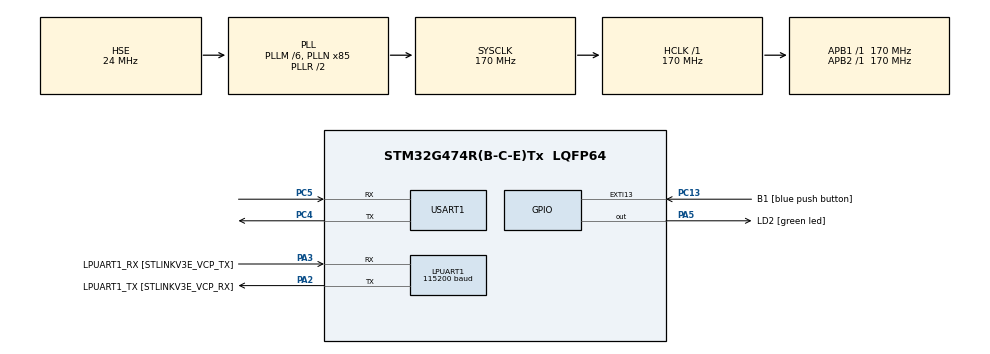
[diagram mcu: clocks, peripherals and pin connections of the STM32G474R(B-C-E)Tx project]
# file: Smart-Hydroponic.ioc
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Mcu.Family=STM32G4
RCC.CortexFreq_Value=170000000
PA14.GPIO_Label=T_SWCLK
LPUART1.WordLength=UART_WORDLENGTH_8B
PC5.Mode=Asynchronous
PC13.GPIO_Label=B1 [blue push button]
RCC.SYSCLKSource=RCC_SYSCLKSOURCE_PLLCLK
ProjectManager.StackSize=0x400
FREERTOS.configENABLE_FPU=1
RCC.HCLKFreq_Value=170000000
RCC.APB2TimFreq_Value=170000000
RCC.AHBFreq_Value=170000000
NVIC.EXTI15_10_IRQn=true\:5\:0\:false\:false\:true\:true\:true\:true
RCC.HSE_VALUE=24000000
FREERTOS.configUSE_TIMERS=1
RCC.RTCClockSelection=RCC_RTCCLKSOURCE_LSE
RCC.ADC12Freq_Value=170000000
PC14-OSC32_IN.Mode=LSE-External-Oscillator
PA14.Mode=Serial_Wire
VP_SYS_VS_tim1.Mode=TIM1
VP_SYS_VS_DBSignals.Mode=DisableDeadBatterySignals
VP_FREERTOS_VS_CMSIS_V1.Mode=CMSIS_V1
Mcu.Package=LQFP64
NVIC.TimeBase=TIM1_UP_TIM16_IRQn
PA2.GPIO_Label=LPUART1_TX [STLINKV3E_VCP_RX]
NVIC.TimeBaseIP=TIM1
RCC.APB1TimFreq_Value=170000000
PC5.Signal=USART1_RX
NVIC.USART1_IRQn=true\:6\:0\:true\:false\:true\:true\:true\:true
PF1-OSC_OUT.Mode=HSE-External-Oscillator
PF1-OSC_OUT.Signal=RCC_OSC_OUT
PC4.Mode=Asynchronous
RCC.HSI48_VALUE=48000000
PA3.Signal=LPUART1_RX
PB3.GPIO_Label=T_SWO
RCC.PLLSourceVirtual=RCC_PLLSOURCE_HSE
PC15-OSC32_OUT.Mode=LSE-External-Oscillator
FREERTOS.Tasks01=defaultTask,0,128,StartDefaultTask,Default,NULL,Dynamic,NULL,NULL
PC13.Signal=GPXTI13
PC4.Signal=USART1_TX
RCC.EXTERNAL_CLOCK_VALUE=12288000
VP_RNG_VS_RNG.Mode=RNG_Activate
PC14-OSC32_IN.Signal=RCC_OSC32_IN
USART1.VirtualMode-Asynchronous=VM_ASYNC
PA13.Signal=SYS_JTMS-SWDIO
PA3.Mode=Asynchronous
ProjectManager.TargetToolchain=STM32CubeIDE
RCC.USBFreq_Value=42500000
PC15-OSC32_OUT.Signal=RCC_OSC32_OUT
PF0-OSC_IN.Mode=HSE-External-Oscillator
PA5.Signal=GPIO_Output
FREERTOS.MEMORY_ALLOCATION=2
board=NUCLEO-G474RE
RCC.VCOOutputFreq_Value=340000000
RCC.ADC345Freq_Value=170000000
RCC.APB2Freq_Value=170000000
PA13.Mode=Serial_Wire
Mcu.Name=STM32G474R(B-C-E)Tx
LPUART1.BaudRate=115200
PA13.GPIO_Label=T_SWDIO
PA2.Signal=LPUART1_TX
PB3.Signal=SYS_JTDO-SWO
RCC.SYSCLKFreq_VALUE=170000000
PA5.GPIO_Label=LD2 [green led]
PA14.Signal=SYS_JTCK-SWCLK
ProjectManager.HeapSize=0x200
RCC.HSI_VALUE=16000000
NVIC.TIM1_UP_TIM16_IRQn=true\:0\:0\:false\:false\:true\:false\:false\:true
RCC.PLLQ=RCC_PLLQ_DIV8
NVIC.PriorityGroup=NVIC_PRIORITYGROUP_4
RCC.PLLM=RCC_PLLM_DIV6
RCC.PLLN=85
PA2.Mode=Asynchronous
PF0-OSC_IN.Signal=RCC_OSC_IN
RCC.APB1Freq_Value=170000000
PA3.GPIO_Label=LPUART1_RX [STLINKV3E_VCP_TX]

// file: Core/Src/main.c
/* USER CODE BEGIN Header */
/**
  ******************************************************************************
  * @file           : main.c
  * @brief          : Main program body
  ******************************************************************************
  * @attention
  *
  * <h2><center>&copy; Copyright (c) 2022 STMicroelectronics.
  * All rights reserved.</center></h2>
  *
  * This software component is licensed by ST under BSD 3-Clause license,
  * the "License"; You may not use this file except in compliance with the
  * License. You may obtain a copy of the License at:
  *                        opensource.org/licenses/BSD-3-Clause
  *
  ******************************************************************************
  */
/* USER CODE END Header */
#include "main.h"
#include "cmsis_os.h"

/* USER CODE BEGIN Includes */
#include <stdio.h>
#include "app.h"

/* USER CODE END Includes */

UART_HandleTypeDef hlpuart1;
UART_HandleTypeDef huart1;

RNG_HandleTypeDef hrng;

osThreadId defaultTaskHandle;

void SystemClock_Config(void);
static void MX_GPIO_Init(void);
static void MX_LPUART1_UART_Init(void);
static void MX_USART1_UART_Init(void);
static void MX_RNG_Init(void);
void StartDefaultTask(void const * argument);

int main(void)
{

  /* MCU Configuration--------------------------------------------------------*/

  /* Reset of all peripherals, Initializes the Flash interface and the Systick. */
  HAL_Init();

  /* Configure the system clock */
  SystemClock_Config();

  /* Initialize all configured peripherals */
  MX_GPIO_Init();
  MX_LPUART1_UART_Init();
  MX_USART1_UART_Init();
  MX_RNG_Init();

  /* Create the thread(s) */
  /* definition and creation of defaultTask */
//  osThreadDef(defaultTask, StartDefaultTask, osPriorityNormal, 0, 128);
//  defaultTaskHandle = osThreadCreate(osThread(defaultTask), NULL);
//
//  /* USER CODE BEGIN RTOS_THREADS */
//////  /* add threads, ... */
//  /* USER CODE END RTOS_THREADS */
//
//  /* Start scheduler */
//  osKernelStart();

  /* We should never get here as control is now taken by the scheduler */
  /* Infinite loop */
  /* USER CODE BEGIN WHILE */

  while(!HAL_GPIO_ReadPin(B1_GPIO_Port, B1_Pin));		// Start button

  if(app_init()){

	  vTaskStartScheduler();
  }

  while (1)
  {

    /* USER CODE END WHILE */

  }
}
void SystemClock_Config(void)
{
  RCC_OscInitTypeDef RCC_OscInitStruct = {0};
  RCC_ClkInitTypeDef RCC_ClkInitStruct = {0};
  RCC_PeriphCLKInitTypeDef PeriphClkInit = {0};

  /** Configure the main internal regulator output voltage
  */
  HAL_PWREx_ControlVoltageScaling(PWR_REGULATOR_VOLTAGE_SCALE1_BOOST);
  /** Initializes the RCC Oscillators according to the specified parameters
  * in the RCC_OscInitTypeDef structure.
  */
  RCC_OscInitStruct.OscillatorType = RCC_OSCILLATORTYPE_HSE;
  RCC_OscInitStruct.HSEState = RCC_HSE_ON;
  RCC_OscInitStruct.PLL.PLLState = RCC_PLL_ON;
  RCC_OscInitStruct.PLL.PLLSource = RCC_PLLSOURCE_HSE;
  RCC_OscInitStruct.PLL.PLLM = RCC_PLLM_DIV6;
  RCC_OscInitStruct.PLL.PLLN = 85;
  RCC_OscInitStruct.PLL.PLLP = RCC_PLLP_DIV2;
  RCC_OscInitStruct.PLL.PLLQ = RCC_PLLQ_DIV8;
  RCC_OscInitStruct.PLL.PLLR = RCC_PLLR_DIV2;
  if (HAL_RCC_OscConfig(&RCC_OscInitStruct) != HAL_OK)
  {
    Error_Handler();
  }
  /** Initializes the CPU, AHB and APB buses clocks
  */
  RCC_ClkInitStruct.ClockType = RCC_CLOCKTYPE_HCLK|RCC_CLOCKTYPE_SYSCLK
                              |RCC_CLOCKTYPE_PCLK1|RCC_CLOCKTYPE_PCLK2;
  RCC_ClkInitStruct.SYSCLKSource = RCC_SYSCLKSOURCE_PLLCLK;
  RCC_ClkInitStruct.AHBCLKDivider = RCC_SYSCLK_DIV1;
  RCC_ClkInitStruct.APB1CLKDivider = RCC_HCLK_DIV1;
  RCC_ClkInitStruct.APB2CLKDivider = RCC_HCLK_DIV1;

  if (HAL_RCC_ClockConfig(&RCC_ClkInitStruct, FLASH_LATENCY_4) != HAL_OK)
  {
    Error_Handler();
  }
  /** Initializes the peripherals clocks
  */
  PeriphClkInit.PeriphClockSelection = RCC_PERIPHCLK_USART1|RCC_PERIPHCLK_LPUART1
                              |RCC_PERIPHCLK_RNG;
  PeriphClkInit.Usart1ClockSelection = RCC_USART1CLKSOURCE_PCLK2;
  PeriphClkInit.Lpuart1ClockSelection = RCC_LPUART1CLKSOURCE_PCLK1;
  PeriphClkInit.RngClockSelection = RCC_RNGCLKSOURCE_PLL;
  if (HAL_RCCEx_PeriphCLKConfig(&PeriphClkInit) != HAL_OK)
  {
    Error_Handler();
  }
}

static void MX_LPUART1_UART_Init(void)
{

  hlpuart1.Instance = LPUART1;
  hlpuart1.Init.BaudRate = 115200;
  hlpuart1.Init.WordLength = UART_WORDLENGTH_8B;
  hlpuart1.Init.StopBits = UART_STOPBITS_1;
  hlpuart1.Init.Parity = UART_PARITY_NONE;
  hlpuart1.Init.Mode = UART_MODE_TX_RX;
  hlpuart1.Init.HwFlowCtl = UART_HWCONTROL_NONE;
  hlpuart1.Init.OneBitSampling = UART_ONE_BIT_SAMPLE_DISABLE;
  hlpuart1.Init.ClockPrescaler = UART_PRESCALER_DIV1;
  hlpuart1.AdvancedInit.AdvFeatureInit = UART_ADVFEATURE_NO_INIT;
  if (HAL_UART_Init(&hlpuart1) != HAL_OK)
  {
    Error_Handler();
  }
  if (HAL_UARTEx_SetTxFifoThreshold(&hlpuart1, UART_TXFIFO_THRESHOLD_1_8) != HAL_OK)
  {
    Error_Handler();
  }
  if (HAL_UARTEx_SetRxFifoThreshold(&hlpuart1, UART_RXFIFO_THRESHOLD_1_8) != HAL_OK)
  {
    Error_Handler();
  }
  if (HAL_UARTEx_DisableFifoMode(&hlpuart1) != HAL_OK)
  {
    Error_Handler();
  }

}

static void MX_USART1_UART_Init(void)
{

  huart1.Instance = USART1;
  huart1.Init.BaudRate = 115200;
  huart1.Init.WordLength = UART_WORDLENGTH_8B;
  huart1.Init.StopBits = UART_STOPBITS_1;
  huart1.Init.Parity = UART_PARITY_NONE;
  huart1.Init.Mode = UART_MODE_TX_RX;
  huart1.Init.HwFlowCtl = UART_HWCONTROL_NONE;
  huart1.Init.OverSampling = UART_OVERSAMPLING_16;
  huart1.Init.OneBitSampling = UART_ONE_BIT_SAMPLE_DISABLE;
  huart1.Init.ClockPrescaler = UART_PRESCALER_DIV1;
  huart1.AdvancedInit.AdvFeatureInit = UART_ADVFEATURE_NO_INIT;
  if (HAL_UART_Init(&huart1) != HAL_OK)
  {
    Error_Handler();
  }
  if (HAL_UARTEx_SetTxFifoThreshold(&huart1, UART_TXFIFO_THRESHOLD_1_8) != HAL_OK)
  {
    Error_Handler();
  }
  if (HAL_UARTEx_SetRxFifoThreshold(&huart1, UART_RXFIFO_THRESHOLD_1_8) != HAL_OK)
  {
    Error_Handler();
  }
  if (HAL_UARTEx_DisableFifoMode(&huart1) != HAL_OK)
  {
    Error_Handler();
  }

}

static void MX_RNG_Init(void)
{

  hrng.Instance = RNG;
  hrng.Init.ClockErrorDetection = RNG_CED_ENABLE;
  if (HAL_RNG_Init(&hrng) != HAL_OK)
  {
    Error_Handler();
  }

}

static void MX_GPIO_Init(void)
{
  GPIO_InitTypeDef GPIO_InitStruct = {0};

  /* GPIO Ports Clock Enable */
  __HAL_RCC_GPIOC_CLK_ENABLE();
  __HAL_RCC_GPIOF_CLK_ENABLE();
  __HAL_RCC_GPIOA_CLK_ENABLE();
  __HAL_RCC_GPIOB_CLK_ENABLE();

  /*Configure GPIO pin Output Level */
  HAL_GPIO_WritePin(LD2_GPIO_Port, LD2_Pin, GPIO_PIN_RESET);

  /*Configure GPIO pin : B1_Pin */
  GPIO_InitStruct.Pin = B1_Pin;
  GPIO_InitStruct.Mode = GPIO_MODE_IT_RISING;
  GPIO_InitStruct.Pull = GPIO_NOPULL;
  HAL_GPIO_Init(B1_GPIO_Port, &GPIO_InitStruct);

  /*Configure GPIO pin : LD2_Pin */
  GPIO_InitStruct.Pin = LD2_Pin;
  GPIO_InitStruct.Mode = GPIO_MODE_OUTPUT_PP;
  GPIO_InitStruct.Pull = GPIO_NOPULL;
  GPIO_InitStruct.Speed = GPIO_SPEED_FREQ_LOW;
  HAL_GPIO_Init(LD2_GPIO_Port, &GPIO_InitStruct);

  /* EXTI interrupt init*/
  HAL_NVIC_SetPriority(EXTI15_10_IRQn, 5, 0);
  HAL_NVIC_EnableIRQ(EXTI15_10_IRQn);

}

void StartDefaultTask(void const * argument)
{
  for(;;)
  {
    osDelay(1);
  }
}

 /**
  * @brief  Period elapsed callback in non blocking mode
  * @note   This function is called  when TIM1 interrupt took place, inside
  * HAL_TIM_IRQHandler(). It makes a direct call to HAL_IncTick() to increment
  * a global variable "uwTick" used as application time base.
  * @param  htim : TIM handle
  * @retval None
  */
void HAL_TIM_PeriodElapsedCallback(TIM_HandleTypeDef *htim)
{
  if (htim->Instance == TIM1) {
    HAL_IncTick();
  }
}

void Error_Handler(void)
{
  __disable_irq();
  while (1)
  {
  }
}

/************************ (C) COPYRIGHT STMicroelectronics *****END OF FILE****/

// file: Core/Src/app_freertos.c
/* USER CODE BEGIN Header */
/**
  ******************************************************************************
  * File Name          : app_freertos.c
  * Description        : Code for freertos applications
  ******************************************************************************
  * @attention
  *
  * <h2><center>&copy; Copyright (c) 2022 STMicroelectronics.
  * All rights reserved.</center></h2>
  *
  * This software component is licensed by ST under Ultimate Liberty license
  * SLA0044, the "License"; You may not use this file except in compliance with
  * the License. You may obtain a copy of the License at:
  *                             www.st.com/SLA0044
  *
  ******************************************************************************
  */
/* USER CODE END Header */

#include "FreeRTOS.h"
#include "task.h"
#include "main.h"

/* GetIdleTaskMemory prototype (linked to static allocation support) */
void vApplicationGetIdleTaskMemory( StaticTask_t **ppxIdleTaskTCBBuffer, StackType_t **ppxIdleTaskStackBuffer, uint32_t *pulIdleTaskStackSize );

/* GetTimerTaskMemory prototype (linked to static allocation support) */
void vApplicationGetTimerTaskMemory( StaticTask_t **ppxTimerTaskTCBBuffer, StackType_t **ppxTimerTaskStackBuffer, uint32_t *pulTimerTaskStackSize );

/* USER CODE BEGIN GET_IDLE_TASK_MEMORY */
static StaticTask_t xIdleTaskTCBBuffer;
static StackType_t xIdleStack[configMINIMAL_STACK_SIZE];

void vApplicationGetIdleTaskMemory( StaticTask_t **ppxIdleTaskTCBBuffer, StackType_t **ppxIdleTaskStackBuffer, uint32_t *pulIdleTaskStackSize )
{
  *ppxIdleTaskTCBBuffer = &xIdleTaskTCBBuffer;
  *ppxIdleTaskStackBuffer = &xIdleStack[0];
  *pulIdleTaskStackSize = configMINIMAL_STACK_SIZE;
  /* place for user code */
}
/* USER CODE END GET_IDLE_TASK_MEMORY */

/* USER CODE BEGIN GET_TIMER_TASK_MEMORY */
static StaticTask_t xTimerTaskTCBBuffer;
static StackType_t xTimerStack[configTIMER_TASK_STACK_DEPTH];

void vApplicationGetTimerTaskMemory( StaticTask_t **ppxTimerTaskTCBBuffer, StackType_t **ppxTimerTaskStackBuffer, uint32_t *pulTimerTaskStackSize )
{
  *ppxTimerTaskTCBBuffer = &xTimerTaskTCBBuffer;
  *ppxTimerTaskStackBuffer = &xTimerStack[0];
  *pulTimerTaskStackSize = configTIMER_TASK_STACK_DEPTH;
  /* place for user code */
}
/* USER CODE END GET_TIMER_TASK_MEMORY */

/************************ (C) COPYRIGHT STMicroelectronics *****END OF FILE****/
